# colorlight register map
Vendor: litex
Registers are 32-bit, read-write, reset 0x0 unless marked. A register's access mark holds for its fields unless they carry their own. Offsets are from the block's base; [hi:lo] are bit positions.

## CTRL
Base 0xF0002000
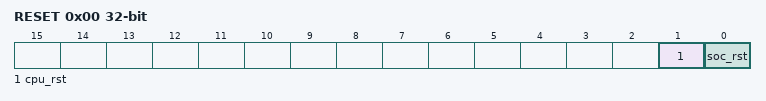
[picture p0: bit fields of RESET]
0x00 RESET
  [1] cpu_rst — Write `1` to this register to reset the CPU(s) of the SoC (Hold Reset)
  [0] soc_rst — Write `1` to this register to reset the full SoC (Pulse Reset)
0x04 SCRATCH reset 0x12345678 — Use this register as a scratch space to verify that software read/write accesses to the Wishbone/CSR bus are working correctly. The initial reset value of 0x12345678 can be used to verify endianness.
0x08 BUS_ERRORS — Total number of Wishbone bus errors (timeouts) since start.

## ETHMAC
Base 0xF0002800
0x00 SRAM_WRITER_SLOT
  [2:0] sram_writer_slot
0x04 SRAM_WRITER_LENGTH
  [10:0] sram_writer_length
0x08 SRAM_WRITER_ERRORS
0x0C SRAM_WRITER_EV_STATUS — This register contains the current raw level of the available event trigger. Writes to this register have no effect.
  [0] available — Level of the ``available`` event
0x10 SRAM_WRITER_EV_PENDING — When a available event occurs, the corresponding bit will be set in this register. To clear the Event, set the corresponding bit in this register.
  [0] available — `1` if a `available` event occurred. This Event is **level triggered** when the signal is **high**.
0x14 SRAM_WRITER_EV_ENABLE — This register enables the corresponding available events. Write a ``0`` to this register to disable individual events.
  [0] available — Write a ``1`` to enable the ``available`` Event
0x18 SRAM_READER_START
  [0] sram_reader_start
0x1C SRAM_READER_READY
  [0] sram_reader_ready
0x20 SRAM_READER_LEVEL
  [1:0] sram_reader_level
0x24 SRAM_READER_SLOT
  [0] sram_reader_slot
0x28 SRAM_READER_LENGTH
  [10:0] sram_reader_length
0x2C SRAM_READER_EV_STATUS — This register contains the current raw level of the event0 event trigger. Writes to this register have no effect.
  [0] event0 — Level of the ``event0`` event
0x30 SRAM_READER_EV_PENDING — When a event0 event occurs, the corresponding bit will be set in this register. To clear the Event, set the corresponding bit in this register.
  [0] event0 — `1` if a this particular event occurred. This Event is triggered on a **rising** edge.
0x34 SRAM_READER_EV_ENABLE — This register enables the corresponding event0 events. Write a ``0`` to this register to disable individual events.
  [0] event0 — Write a ``1`` to enable the ``event0`` Event
0x38 PREAMBLE_CRC reset 0x1
  [0] preamble_crc
0x3C RX_DATAPATH_PREAMBLE_ERRORS
0x40 RX_DATAPATH_CRC_ERRORS
0x44 IP_ADDRESS reset 0xA0B06FA
0x48 MAC_ADDRESS1 reset 0x10E2 — Bits 32-47 of `ETHMAC_MAC_ADDRESS`. The value won't take effect until `ETHMAC_MAC_ADDRESS0` is written.
  [31:0] mac_address
0x4C MAC_ADDRESS0 reset 0xD5000001 — Bits 0-31 of `ETHMAC_MAC_ADDRESS`. Writing this register triggers an update of `ETHMAC_MAC_ADDRESS`.
  [31:0] mac_address
0x50 DBG_MAC1 — Bits 32-47 of `ETHMAC_DBG_MAC`. Last parsed destination MAC
  [31:0] dbg_mac
0x54 DBG_MAC0 — Bits 0-31 of `ETHMAC_DBG_MAC`.
  [31:0] dbg_mac
0x58 DBG_ETHERTYPE — Last parsed ethertype
  [15:0] dbg_ethertype
0x5C C_CORE — Beats out of the MAC core
0x60 C_SPLIT2 — Beats into the hardware branch
0x64 C_GATE_OUT — Beats out of the gate
0x68 C_NARROW_OUT — Beats out of the 32->8 converter
0x6C C_DROPPED — Packets dropped by the gate
0x70 N_GATE — Packets leaving the always-ready gate
0x74 N_NARROW — Packets leaving the 32->8 converter
0x78 N_MAC — Packets passing the MAC filter
0x7C N_IP — Packets passing the IP filter
0x80 N_UDP — Payloads passing the UDP port filter

## ETHPHY
Base 0xF0003000
0x00 CRG_RESET
  [0] crg_reset
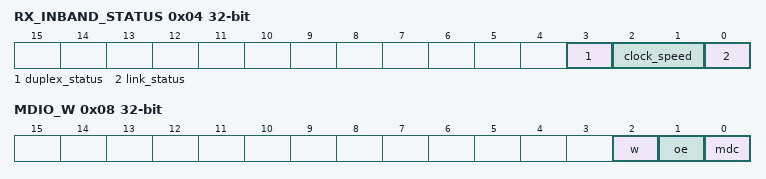
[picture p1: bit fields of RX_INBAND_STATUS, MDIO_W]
0x04 RX_INBAND_STATUS
  [3] duplex_status, [2:1] clock_speed, [0] link_status
0x08 MDIO_W
  [2] w, [1] oe, [0] mdc
0x0C MDIO_R
  [0] r

## HUB75_PALETTE
Base 0xF0003800
0x00 HUB75_PALETTE — 32 x 256-bit memory
